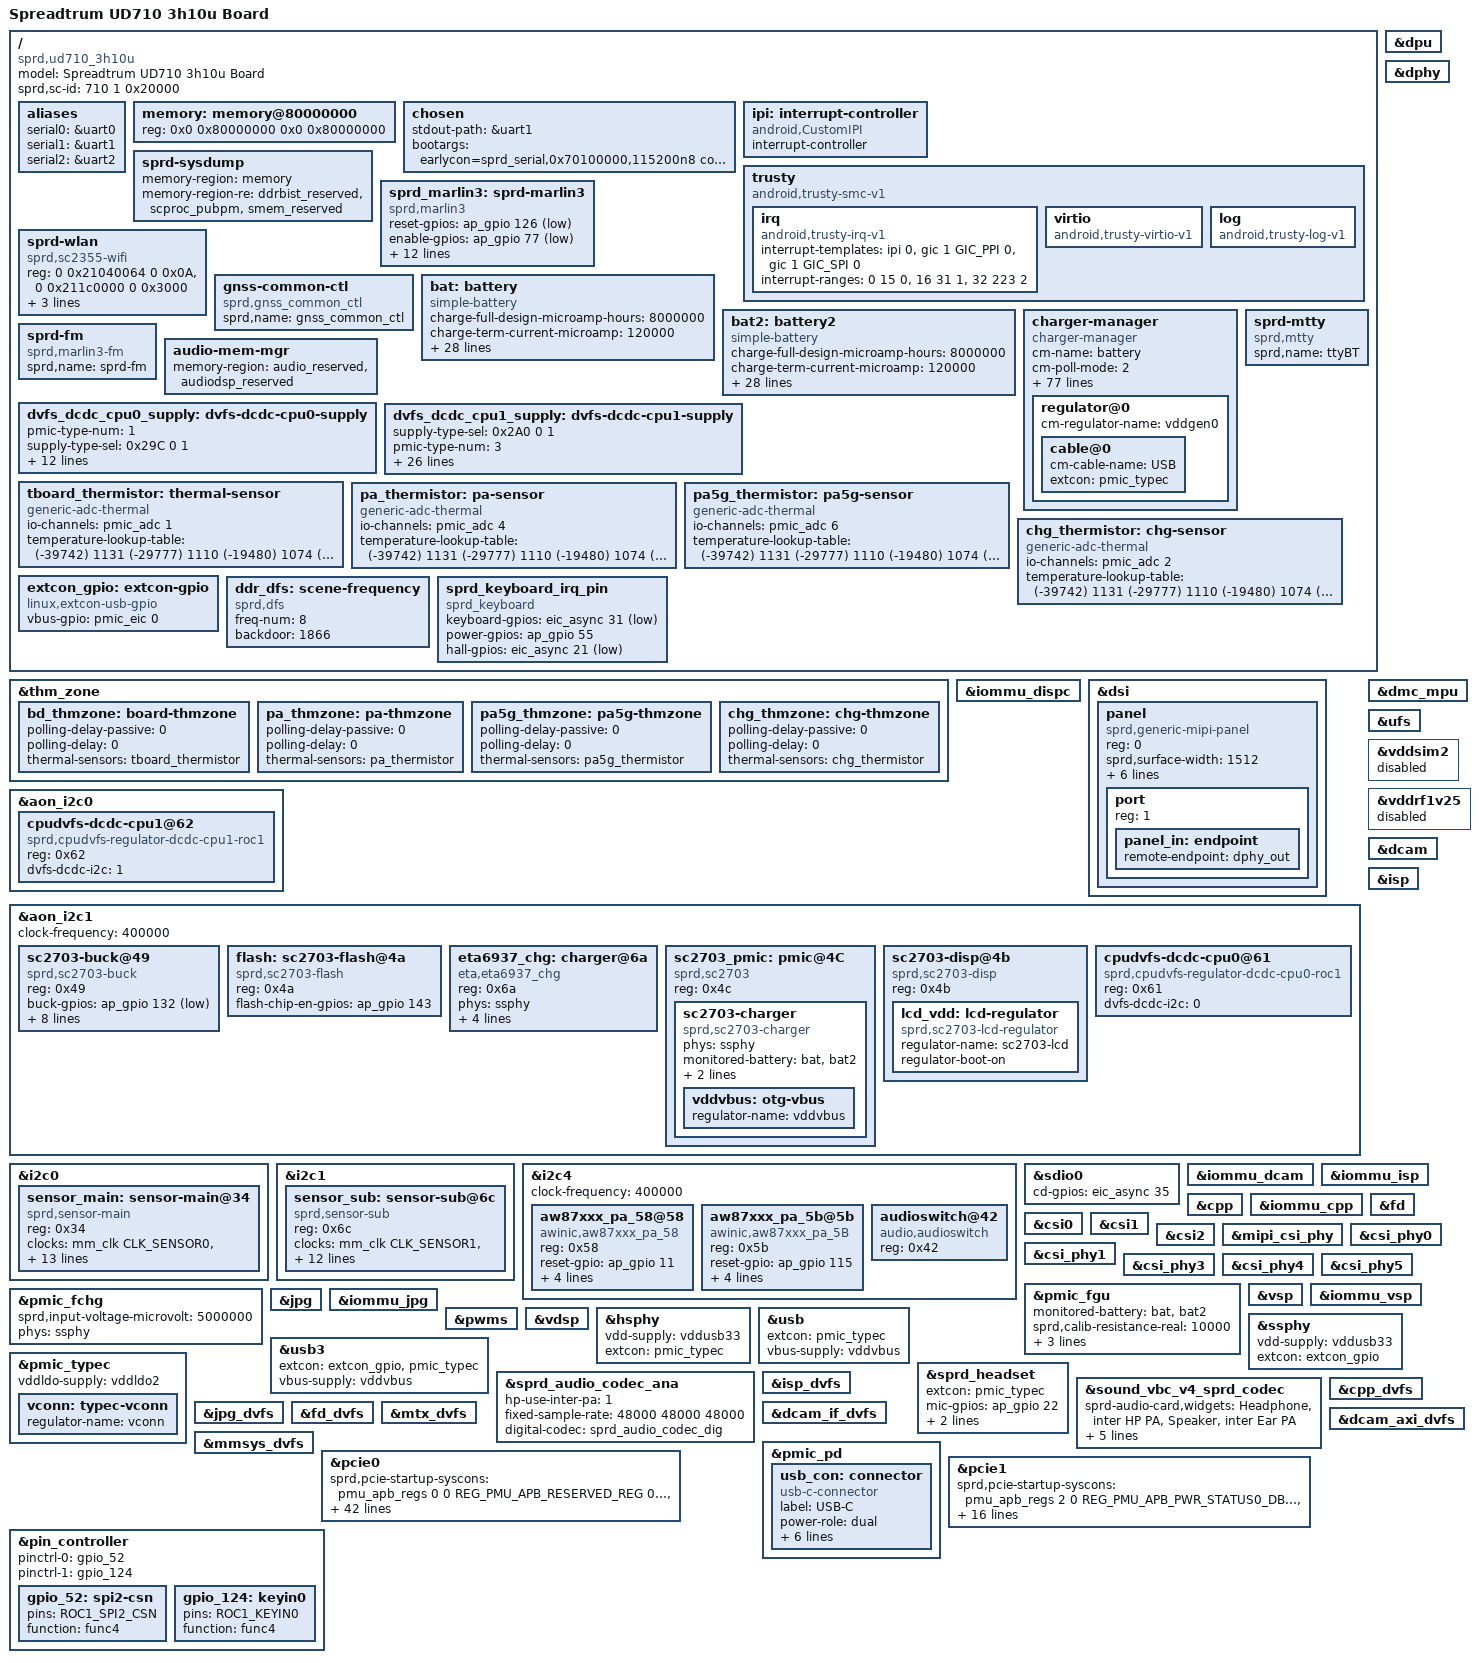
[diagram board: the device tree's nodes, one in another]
/*
 * Spreadtrum Roc1 board DTS file
 *
 * Copyright (C) 2018, Spreadtrum Communications Inc.
 *
 * This file is licensed under a dual GPLv2 or X11 license.
 */
/dts-v1/;

#include <dt-bindings/gpio/gpio.h>
#include <dt-bindings/usb/pd.h>

#include "ud710.dtsi"
#include "sc2730.dtsi"
#include "ud710-3h10u-mach.dtsi"
#include "ud710-2h10-modem.dtsi"
#include "sprd-sound-fe-be.dtsi"
#include "lcd/lcd_dummy_mipi.dtsi"

#include "lcd/lcd_rm69380_lattice_fpga_mipi.dtsi"

/ {
	model = "Spreadtrum UD710 3h10u Board";

	compatible = "sprd,ud710_3h10u", "sprd,ud710";

	sprd,sc-id = <710 1 0x20000>;

	aliases {
		serial0 = &uart0;
		serial1 = &uart1;
		serial2 = &uart2;
	};

	memory: memory@80000000 {
		device_type = "memory";
		reg = <0x0 0x80000000 0x0 0x80000000>;
	};

	chosen {
		stdout-path = &uart1;
		bootargs = "earlycon=sprd_serial,0x70100000,115200n8 console=ttyS1,115200n8 loop.max_part=7 loglevel=1 init=/init root=/dev/raw0 rw rootwait androidboot.hardware=ud710_3h10u androidboot.dtbo_idx=0 printk.devkmsg=on pcie_ports=compat";
	};

	ipi: interrupt-controller {
		compatible = "android,CustomIPI";
		#interrupt-cells = <1>;
		interrupt-controller;
	};

	trusty {
		compatible = "android,trusty-smc-v1";

		irq {
			compatible = "android,trusty-irq-v1";
			interrupt-templates = <&ipi 0>,
						<&gic 1 GIC_PPI 0>,
						<&gic 1 GIC_SPI 0>;
			interrupt-ranges = < 0  15 0>,
						<16  31 1>,
						<32 223 2>;
		};

		virtio {
			compatible = "android,trusty-virtio-v1";
		};

		log {
			compatible = "android,trusty-log-v1";
		};
	};

	sprd-sysdump {
		memory-region = <&memory>;
		memory-region-re = <&ddrbist_reserved>, <&scproc_pubpm>, <&smem_reserved>;
	};

	sprd_marlin3: sprd-marlin3 {
		compatible = "sprd,marlin3";
		reset-gpios = <&ap_gpio 126 GPIO_ACTIVE_LOW>;
		enable-gpios = <&ap_gpio 77 GPIO_ACTIVE_LOW>;
		m2-to-ap-irq-gpios = <&ap_gpio 96 GPIO_ACTIVE_LOW>;
		xtal-26m-clk-type = "TCXO";
		/* no need config dvdd12 because of share vddmem to DDR */
		avdd12-supply = <&vddgen1>;
		avdd33-supply = <&vddwifipa>;
		dcxo18-supply = <&vddldo0>;
		clock-names = "clk_32k","source","enable";
		clocks = <&aon_clk CLK_AON_AUX0>,
			 <&ext_32k>,
			 <&aonapb_gate CLK_AUX0_EB>;
		sprd,btwf-file-name = "/dev/block/by-name/wcnmodem";
		sprd,gnss-file-name = "/dev/block/by-name/gnssmodem";
		sprd,rc-ctrl = <&pcie0>;
	};

	sprd-wlan {
		compatible = "sprd,sc2355-wifi";
		reg = <0 0x21040064 0 0x0A>,
		      <0 0x211c0000 0 0x3000>;
		reg-names = "wifi_ipaqos",
			    "pam_wifi_reg_base_remap";
		syscons = <&ipa_ahb_regs
			   REG_IPA_AHB_IPA_EB
			   MASK_IPA_AHB_PAM_WIFI_EB>;
		syscon-names = "enable";
	};

	gnss-common-ctl {
		compatible = "sprd,gnss_common_ctl";
		sprd,name = "gnss_common_ctl";
	};

	bat: battery {
		compatible = "simple-battery";
		charge-full-design-microamp-hours = <8000000>;
		charge-term-current-microamp = <120000>;
		constant_charge_voltage_max_microvolt = <4400000>;
		factory-internal-resistance-micro-ohms = <80000>;
		voltage-min-design-microvolt = <3490000>;
		ocv-capacity-celsius = <20>;
		ocv-capacity-table-0 = <4334000 100>, <4272000 95>, <4218000 90>,
					<4160000 85>, <4109000 80>, <4068000 75>,
					<3999000 70>, <3964000 65>, <3923000 60>,
					<3876000 55>, <3847000 50>, <3824000 45>,
					<3803000 40>, <3787000 35>, <3773000 30>,
					<3757000 25>, <3742000 20>, <3720000 15>,
					<3689000 10>, <3675000 5>, <3400000 0>;
		voltage-temp-table = <1084000 800>, <975000 850>, <868000 900>,
				      <765000 950>, <668000 1000>, <580000 1050>,
				      <501000 1100>, <430000 1150>, <369000 1200>,
				      <315000 1250>, <270000 1300>, <231000 1350>,
				      <197000 1400>, <169000 1450>, <145000 1500>,
				      <125000 1550>, <108000 1600>, <93000 1650>;
		capacity-temp-table = <45 100>, <25 100>, <10 97>, <0 95>, <(-10) 82>, <(-20) 62>;
		resistance-temp-table = <45 100>, <25 100>, <10 483>, <0 680>, <(-10) 789>, <(-20) 816>;
		charge-sdp-current-microamp = <500000 500000>;
		charge-dcp-current-microamp = <2500000 3000000>;
		charge-cdp-current-microamp = <1500000 1500000>;
		charge-unknown-current-microamp = <2000000 2500000>;
		charge-fchg-current-microamp = <1650000 1000000>;
	};
	
	bat2: battery2 {
		compatible = "simple-battery";
		charge-full-design-microamp-hours = <8000000>;
		charge-term-current-microamp = <120000>;
		constant_charge_voltage_max_microvolt = <4400000>;
		factory-internal-resistance-micro-ohms = <80000>;
		voltage-min-design-microvolt = <3490000>;
		ocv-capacity-celsius = <20>;
		ocv-capacity-table-0 = <4326000 100>, <4262000 95>, <4209000 90>,
					<4150000 85>, <4100000 80>, <4050000 75>,
					<3999000 70>, <3964000 65>, <3918000 60>,
					<3872000 55>, <3838000 50>, <3817000 45>,
					<3798000 40>, <3782000 35>, <3769000 30>,
					<3756000 25>, <3737000 20>, <3715000 15>,
					<3683000 10>, <3672000 5>, <3400000 0>;
		voltage-temp-table = <1084000 800>, <975000 850>, <868000 900>,
				      <765000 950>, <668000 1000>, <580000 1050>,
				      <501000 1100>, <430000 1150>, <369000 1200>,
				      <315000 1250>, <270000 1300>, <231000 1350>,
				      <197000 1400>, <169000 1450>, <145000 1500>,
				      <125000 1550>, <108000 1600>, <93000 1650>;
		capacity-temp-table = <45 100>, <25 100>, <10 97>, <0 95>, <(-10) 82>, <(-20) 62>;
		resistance-temp-table = <45 100>, <25 100>, <10 483>, <0 680>, <(-10) 789>, <(-20) 816>;
		charge-sdp-current-microamp = <500000 500000>;
		charge-dcp-current-microamp = <2500000 3000000>;
		charge-cdp-current-microamp = <1500000 1500000>;
		charge-unknown-current-microamp = <2000000 2500000>;
		charge-fchg-current-microamp = <1650000 1000000>;
	};

	charger-manager {
		compatible = "charger-manager";
		cm-name = "battery";
		cm-poll-mode = <2>;
		cm-poll-interval = <15000>;
		cm-battery-stat = <2>;

		cm-fullbatt-vchkdrop-ms = <30000>;
		cm-fullbatt-vchkdrop-volt = <60000>;
		cm-fullbatt-voltage = <4320000 4320000>;
		cm-first-fullbatt-current = <150000>;
		cm-fullbatt-current = <200000>;
		cm-fullbatt-capacity = <100>;

		cm-num-chargers = <2>;
		cm-num-fast-chargers = <1>;
		cm-chargers = "sc2703_charger","eta6937_charger";
		cm-fast-chargers = "sc2730_fast_charger";
		cm-fuel-gauge = "sc27xx-fgu";

		/* in deci centigrade */
		cm-battery-cold = <200>;
		cm-battery-cold-in-minus;
		cm-battery-hot = <800>;
		cm-battery-temp-diff = <100>;

		/* Allow charging for 10hr */
		cm-charging-max = <36000000>;
		/* recovery charging after stop charging 3hr */
		cm-discharging-max = <10800000>;

		/* the interval to feed charger watchdog */
		cm-wdt-interval = <60>;

		/* drop voltage in microVolts to allow shutdown */
		cm-shutdown-voltage = <3400000>;

		/* when 99% of the time is exceeded, it will be forced to 100% */
		cm-tickle-time-out = <500>;

		/* how much time to allow capacity change */
		cm-one-cap-time = <30>;

		/* when the safe charging voltage is exceeded, stop charging */
		cm-charge-voltage-max = <6500000>;
		/* drop voltage in microVolts to restart charging */
		cm-charge-voltage-drop = <700000>;

		/* when the safe charging voltage is exceeded, stop charging */
		cm-fast-charge-voltage-max = <10500000>;
		/* drop voltage in microVolts to restart charging */
		cm-fast-charge-voltage-drop = <700000>;

		cm-double-ic-total-limit-current = <2000000>;
		cm-fchg-compensation-current = <3600000>;
        cm-dcp-jeita-temp-table = <1000 1030 0 4100000>, <1100 1130 1550000 4100000>,
            <1450 1420 2500000 4350000>, <1600 1570 1550000 4100000>;
        cm-dcp-jeita-temp-table-1 = <1000 1030 0 4100000>, <1100 1130 1550000 4100000>,
            <1450 1420 2500000 4350000>, <1600 1570 1550000 4100000>;
        cm-sdp-jeita-temp-table = <1000 1030 0 4100000>, <1100 1130 500000 4100000>,
            <1450 1420 500000 4350000>, <1600 1570 500000 4100000>;
        cm-sdp-jeita-temp-table-1 = <1000 1030 0 4100000>, <1100 1130 500000 4100000>,
            <1450 1420 500000 4350000>, <1600 1570 500000 4100000>;
        cm-cdp-jeita-temp-table = <1000 1030 0 4100000>, <1100 1130 700000 4100000>,
            <1450 1420 2000000 4350000>, <1600 1570 1550000 4100000>;
        cm-cdp-jeita-temp-table-1 = <1000 1030 0 4100000>, <1100 1130 700000 4100000>,
            <1450 1420 2000000 4350000>, <1600 1570 1550000 4100000>;
        cm-unknown-jeita-temp-table = <1000 1030 0 4100000>, <1100 1130 1550000 4100000>,
            <1450 1420 2000000 4350000>, <1600 1570 1550000 4100000>;
        cm-unknown-jeita-temp-table-1 = <1000 1030 0 4100000>, <1100 1130 1550000 4100000>,
            <1450 1420 2000000 4350000>, <1600 1570 1550000 4100000>;
        cm-fchg-jeita-temp-table = <1000 1030 0 4100000>, <1100 1130 1000000 4100000>,
            <1450 1420 1650000 4350000>, <1600 1570 1000000 4100000>;
        cm-fchg-jeita-temp-table-1 = <1000 1030 0 4100000>, <1100 1130 1000000 4100000>,
            <1450 1420 1650000 4350000>, <1600 1570 1000000 4100000>;


		monitored-battery = <&bat &bat2>;
		cm-capacity-track;

		regulator@0 {
			cm-regulator-name = "vddgen0";
			cable@0 {
				cm-cable-name = "USB";
				extcon = <&pmic_typec>;
			};
		};
	};

	sprd-mtty {
		compatible = "sprd,mtty";
		sprd,name = "ttyBT";
	};

	sprd-fm {
		compatible = "sprd,marlin3-fm";
		sprd,name = "sprd-fm";
	};

	audio-mem-mgr {
		memory-region = <&audio_reserved &audiodsp_reserved>;
	};

	dvfs_dcdc_cpu0_supply: dvfs-dcdc-cpu0-supply {
		pmic-type-num = <1>;
		supply-type-sel = <0x29C 0 1>;
		top-dvfs-i2c-state = <0x88 4 0xF>;
		voltage-grade-num = <7>;
		voltage-grade = <0 0x2D 0x260 0 0xFFFF>,	/* 0.75 */
				<1 0x32 0x260 16 0xFFFF>,	/* 0.80 */
				<2 0x37 0x264 0 0xFFFF>,	/* 0.85 */
				<3 0x3C 0x264 16 0xFFFF>,	/* 0.90 */
				<4 0x41 0x268 0 0xFFFF>,	/* 0.95 */
				<5 0x46 0x268 16 0xFFFF>,	/* 1.00 */
				<6 0x4B 0x26C 0 0xFFFF>;	/* 1.05 */
		tuning-latency-us = <200>;
		chnl-in-i2c = <1>;
		slew-rate = <20000>; /* 20000uV/us */
	};

	dvfs_dcdc_cpu1_supply: dvfs-dcdc-cpu1-supply {
		supply-type-sel = <0x2A0 0 1>;
		pmic-type-num = <3>;
		top-dvfs-i2c-state = <0x8C 4 0xF>;
		voltage-grade-num = <7>;
		voltage-grade = <0 0x4B 0x280 0 0xFFFF>,	/* 0.75 */
				<1 0x50 0x280 16 0xFFFF>,	/* 0.80 */
				<2 0x55 0x284 0 0xFFFF>,	/* 0.85 */
				<3 0x5A 0x284 16 0xFFFF>,	/* 0.90 */
				<4 0x5F 0x288 0 0xFFFF>,	/* 0.95 */
				<5 0x64 0x288 16 0xFFFF>,	/* 1.00 */
				<6 0x69 0x28c 0 0xFFFF>;	/* 1.05 */
		voltage-up-delay = <50 0x130 0 0xffff 0x1600>,
				<100 0x130 16 0xffff 0x1a00>,
				<150 0x134 0 0xffff 0x1f00>,
				<200 0x134 16 0xffff 0x2400>,
				<250 0x138 0 0xffff 0x2900>,
				<300 0x138 16 0xffff 0x2e00>,
				<350 0x13c 0 0xffff 0x3300>;
		voltage-down-delay = <50 0x140 0 0xffff 0x1600>,
				<100 0x140 16 0xffff 0x1a00>,
				<150 0x144 0 0xffff 0x1f00>,
				<200 0x144 16 0xffff 0x2400>,
				<250 0x148 0 0xffff 0x2900>,
				<300 0x148 16 0xffff 0x2e00>,
				<350 0x14c 0 0xffff 0x3300>;
		tuning-latency-us = <200>;
		chnl-in-i2c = <1>;
		slew-rate = <10000>; /* 10000uV/us */
	};

	tboard_thermistor:thermal-sensor {
		compatible = "generic-adc-thermal";
		#thermal-sensor-cells = <0>;
		io-channels = <&pmic_adc 1>;
		io-channel-names = "sensor-channel";
		temperature-lookup-table = <	(-39742) 1131
						(-29777) 1110
						(-19480) 1074
						(-4679) 983
						10110 838
						24805 654
						44922 413
						54903 316
						64895 238
						74884 178
						84883 133
						94883 100
						104880 75
						114889 57
						124872 43 >;
	};

	pa_thermistor:pa-sensor {
		compatible = "generic-adc-thermal";
		#thermal-sensor-cells = <0>;
		io-channels = <&pmic_adc 4>;
		io-channel-names = "sensor-channel";
		temperature-lookup-table = <	(-39742) 1131
			(-29777) 1110
			(-19480) 1074
			(-4679) 983
			10110 838
			24805 654
			44922 413
			54903 316
			64895 238
			74884 178
			84883 133
			94883 100
			104880 75
			114889 57
			124872 43 >;
	};

	pa5g_thermistor:pa5g-sensor {
		compatible = "generic-adc-thermal";
		#thermal-sensor-cells = <0>;
		io-channels = <&pmic_adc 6>;
		io-channel-names = "sensor-channel";
		temperature-lookup-table = <	(-39742) 1131
			(-29777) 1110
			(-19480) 1074
			(-4679) 983
			10110 838
			24805 654
			44922 413
			54903 316
			64895 238
			74884 178
			84883 133
			94883 100
			104880 75
			114889 57
			124872 43 >;
	};

	chg_thermistor:chg-sensor {
		compatible = "generic-adc-thermal";
		#thermal-sensor-cells = <0>;
		io-channels = <&pmic_adc 2>;
		io-channel-names = "sensor-channel";
		temperature-lookup-table = <	(-39742) 1131
			(-29777) 1110
			(-19480) 1074
			(-4679) 983
			10110 838
			24805 654
			44922 413
			54903 316
			64895 238
			74884 178
			84883 133
			94883 100
			104880 75
			114889 57
			124872 43 >;
	};
	extcon_gpio: extcon-gpio {
		compatible = "linux,extcon-usb-gpio";
		vbus-gpio = <&pmic_eic 0 GPIO_ACTIVE_HIGH>;
	};

	ddr_dfs: scene-frequency {
		compatible = "sprd,dfs";
		freq-num = <8>;
		backdoor = <1866>;
	};
    sprd_keyboard_irq_pin {
        compatible = "sprd_keyboard";
        keyboard-gpios = <&eic_async 31 GPIO_ACTIVE_LOW>;
        power-gpios = <&ap_gpio 55 0>;
        hall-gpios = <&eic_async 21 GPIO_ACTIVE_LOW>;
    };
};

&dpu {
	status = "okay";
};

&thm_zone {
	bd_thmzone: board-thmzone {
		polling-delay-passive = <0>;
		polling-delay = <0>;
		thermal-sensors = <&tboard_thermistor>;
	};
	pa_thmzone: pa-thmzone {
		polling-delay-passive = <0>;
		polling-delay = <0>;
		thermal-sensors = <&pa_thermistor>;
	};

	pa5g_thmzone: pa5g-thmzone {
		polling-delay-passive = <0>;
		polling-delay = <0>;
		thermal-sensors = <&pa5g_thermistor>;
	};

	chg_thmzone: chg-thmzone {
		polling-delay-passive = <0>;
		polling-delay = <0>;
		thermal-sensors = <&chg_thermistor>;
	};
};

&iommu_dispc {
	status = "okay";
};

&dsi {
	status = "okay";
	#address-cells = <1>;
	#size-cells = <0>;

	panel: panel {
		compatible = "sprd,generic-mipi-panel";
		#address-cells = <1>;
		#size-cells = <0>;
		reg = <0>;
		sprd,surface-width = <1512>;
		sprd,surface-height = <2072>;
		reset-gpio = <&ap_gpio 50 GPIO_ACTIVE_HIGH>;
		lcd1v8-gpio = <&ap_gpio 60 GPIO_ACTIVE_HIGH>;
		fpga1v8-gpio = <&ap_gpio 72 GPIO_ACTIVE_HIGH>;
		fpga1v2-gpio = <&ap_gpio 73 GPIO_ACTIVE_HIGH>;
		//fpgarst-gpio = <&ap_gpio 137 GPIO_ACTIVE_HIGH>;
		power-supply = <&lcd_vdd>;
		port {
			reg = <1>;
			panel_in: endpoint {
				remote-endpoint = <&dphy_out>;
			};
		};
	};
};

//&vddldo2 {
//	regulator-always-on;
//	status = "okay";
//};
//
//&vddldo1 {
//	regulator-always-on;
//	status = "okay";
//};

&dphy {
	status = "okay";
};

&aon_i2c0 {
	status = "okay";

	/* A virtual i2c device */
	cpudvfs-dcdc-cpu1@62{
		compatible = "sprd,cpudvfs-regulator-dcdc-cpu1-roc1";
		reg = <0x62>;
		dvfs-dcdc-i2c = <1>;
	};
};

&aon_i2c1 {
	status = "okay";
	clock-frequency = <400000>;

	sc2703-buck@49 {
		compatible = "sprd,sc2703-buck";
		reg = <0x49>;
		buck-gpios = <&ap_gpio 132 GPIO_ACTIVE_LOW>;

		sprd,buck-ch1-b-out = <1000000>;

		regulator-name = "sc2703-buck";
		regulator-min-microvolt = < 300000>;
		regulator-max-microvolt = <1570000>;
		regulator-min-microamp = <5600000>;
		regulator-max-microamp = <10800000>;
		regulator-boot-on;
		regulator-always-on;
	};

	flash: sc2703-flash@4a {
		compatible = "sprd,sc2703-flash";
		reg = <0x4a>;
		flash-chip-en-gpios = <&ap_gpio 143 0>;
	};

	eta6937_chg: charger@6a {
		compatible = "eta,eta6937_chg";
		reg = <0x6a>;
		phys = <&ssphy>;
		monitored-battery = <&bat &bat2>;
		chg-enable-gpios = <&ap_gpio 83 GPIO_ACTIVE_HIGH>;
		extcon = <&pmic_typec>;
		status="okay";
		role-slave;
	};

	sc2703_pmic: pmic@4C {
		compatible = "sprd,sc2703";
		reg = <0x4c>;
		sc2703-charger {
			compatible = "sprd,sc2703-charger";
			phys = <&ssphy>;
			monitored-battery = <&bat &bat2>;
			extcon = <&pmic_typec>, <&pmic_pd>;
			sprd,long-key-detection;
			vddvbus:otg-vbus {
				regulator-name = "vddvbus";
			};
		};
	};
	sc2703-disp@4b {
		compatible = "sprd,sc2703-disp";
		reg = <0x4b>;

		lcd_vdd: lcd-regulator {
			compatible = "sprd,sc2703-lcd-regulator";
			regulator-name = "sc2703-lcd";
			regulator-boot-on;
		};
	};

	/* A virtual i2c device */
	cpudvfs-dcdc-cpu0@61{
		compatible = "sprd,cpudvfs-regulator-dcdc-cpu0-roc1";
		reg = <0x61>;
		dvfs-dcdc-i2c = <0>;
	};
};

&i2c0 {
	status = "okay";

	sensor_main: sensor-main@34 {
		compatible = "sprd,sensor-main";
		reg = <0x34>;

		clock-names = "clk_src","sensor_eb",
			"clk_96m","clk_76m8",
			"clk_48m","clk_26m";
		clocks = <&mm_clk CLK_SENSOR0>,<&mm_gate CLK_MM_SENSOR0_EB>,
			<&g12_pll CLK_TWPLL_96M>,<&g12_pll CLK_TWPLL_76M8>,
			<&g12_pll CLK_TWPLL_48M>,<&ext_26m>;
		vddio-supply = <&vddcamio>;
		vddcama-supply = <&vddcama0>;
		vddcamd-supply = <&vddcamd0>;
		vddcammot-supply = <&vddcammot>;
		sprd,phyid = <0>;
		csi = <&csi0>;
		reset-gpios = <&ap_gpio 44 0>;
		power-down-gpios = <&ap_gpio 46 0>;
		avdd-gpios = <&ap_gpio 162 0>;

		status = "okay";
	};
};

&i2c1 {
	status = "okay";

	sensor_sub: sensor-sub@6c {
		compatible = "sprd,sensor-sub";
		reg = <0x6c>;

		clock-names = "clk_src","sensor_eb",
			"clk_96m","clk_76m8",
			"clk_48m","clk_26m";
		clocks = <&mm_clk CLK_SENSOR1>,<&mm_gate CLK_MM_SENSOR1_EB>,
			<&g12_pll CLK_TWPLL_96M>,<&g12_pll CLK_TWPLL_76M8>,
			<&g12_pll CLK_TWPLL_48M>,<&ext_26m>;
		vddio-supply = <&vddcamio>;
		vddcama-supply = <&vddcama1>;
		vddcamd-supply = <&vddcamd1>;
		vddcammot-supply = <&vddcammot>;
		sprd,phyid = <5>;
		csi = <&csi1>;
		reset-gpios = <&ap_gpio 45 0>;
		power-down-gpios = <&ap_gpio 47 0>;
		/*avdd-gpios = <&ap_gpio 140 0>;*/

		status = "okay";
	};
/*
	sensor_main2: sensor-main2@20 {
		compatible = "sprd,sensor-main2";
		reg = <0x20>;

		clock-names = "clk_src","sensor_eb",
			"clk_96m","clk_76m8",
			"clk_48m","clk_26m";
		clocks = <&mm_clk CLK_SENSOR0>,<&mm_gate CLK_MM_SENSOR0_EB>,
			<&g12_pll CLK_TWPLL_96M>,<&g12_pll CLK_TWPLL_76M8>,
			<&g12_pll CLK_TWPLL_48M>,<&ext_26m>;
		vddio-supply = <&vddcamio>;
		vddcama-supply = <&vddcama1>;
		vddcamd-supply = <&vddcamd1>;
		vddcammot-supply = <&vddcammot>;
		sprd,phyid = <4>;
		csi = <&csi1>;
		reset-gpios = <&ap_gpio 138 0>;
		power-down-gpios = <&ap_gpio 137 0>;

		status = "okay";
	};
*/
};

&i2c4 {
	status = "okay";
	clock-frequency = <400000>;

    aw87xxx_pa_58@58 {
        compatible = "awinic,aw87xxx_pa_58";
        reg = <0x58>;
        reset-gpio = <&ap_gpio 11 0>;
        monitor-flag = <1>;
        driver-num = < 0 >;
        monitor-timer-val = <3000>;
        monitor-timer-count-max = <5>;
        status = "okay";
    };

    aw87xxx_pa_5b@5b {
        compatible = "awinic,aw87xxx_pa_5B";
        reg = <0x5b>;
        reset-gpio = <&ap_gpio 115 0>;
        monitor-flag = <1>;
        driver-num = < 1 >;
        monitor-timer-val = <3000>;
        monitor-timer-count-max = <5>;
        status = "okay";
    };
    audioswitch@42 {
	status = "okay";
	compatible = "audio,audioswitch";
	reg = <0x42>;
    };
};

&dmc_mpu {
	status = "okay";
};

&sdio0 {
	cd-gpios = <&eic_async 35 GPIO_ACTIVE_HIGH>;
};

&ufs {
	status = "okay";
};


&vddsim2 {
	status = "disabled";
};

&vddrf1v25 {
	status = "disabled";
};

&dcam {
	status = "okay";
};

&iommu_dcam {
	status = "okay";
};

&isp {
	status = "okay";
};

&iommu_isp {
	status = "okay";
};

&cpp {
	status = "okay";
};

&iommu_cpp {
	status = "okay";
};

&fd{
	status = "okay";
};

&csi0{
	status = "okay";
};

&csi1{
	status = "okay";
};

&csi2{
	status = "okay";
};

&mipi_csi_phy {
	status = "okay";
};

&csi_phy0{
	status = "okay";
};

&csi_phy1{
	status = "okay";
};

&csi_phy3{
	status = "okay";
};

&csi_phy4{
	status = "okay";
};

&csi_phy5{
	status = "okay";
};

&pmic_fgu {
	monitored-battery = <&bat &bat2>;
	sprd,calib-resistance-real = <10000>;
	sprd,calib-resistance-spec = <20000>;
	first-calib-voltage = <3630000>;
	first-calib-capacity = <50>;
};

&pmic_fchg {
	sprd,input-voltage-microvolt = <5000000>;
	phys = <&ssphy>;
};

&vsp {
	status = "okay";
};

&iommu_vsp {
	status = "okay";
};

&jpg {
	status = "okay";
};

&iommu_jpg {
	status = "okay";
};

&pwms {
	status = "okay";
};

&vdsp {
	status = "okay";
};

&hsphy {
	vdd-supply = <&vddusb33>;
	extcon = <&pmic_typec>;
	status = "okay";
};

&usb {
	extcon = <&pmic_typec>;
	vbus-supply = <&vddvbus>;
	status = "okay";
};

&ssphy {
	vdd-supply = <&vddusb33>;
	extcon = <&extcon_gpio>;
	status = "okay";
};

&usb3 {
	extcon = <&extcon_gpio>, <&pmic_typec>;
	vbus-supply = <&vddvbus>;
	status = "okay";
};

&pmic_typec {
	vddldo-supply = <&vddldo2>;
	status = "okay";
	vconn: typec-vconn {
		regulator-name = "vconn";
	};
};

&sprd_headset {
	status = "okay";
	extcon = <&pmic_typec>;
	mic-gpios = <&ap_gpio 22 GPIO_ACTIVE_HIGH>;
	lr-gpios = <&ap_gpio 23 GPIO_ACTIVE_HIGH>;
	sprd,3pole-adc-threshold = <112>;
};

&sprd_audio_codec_ana {
	status = "okay";
	hp-use-inter-pa = <1>;
	fixed-sample-rate = <48000 48000 48000>;
	digital-codec = <&sprd_audio_codec_dig>;
};

&sound_vbc_v4_sprd_codec {

    status = "okay";
    sprd-audio-card,widgets =
        "Headphone", "inter HP PA",
        "Speaker", "inter Ear PA";
    sprd-audio-card,routing =
        "HPMIC Pin", "HP Mic Jack",
        "MIC Pin", "Mic Jack",
        "MIC2 Pin", "Aux Mic Jack",
        "inter HP PA", "HP Pin",
        "Ext Spk", "HP Pin",
        "DMIC Pin", "DMic Jack",
        "DMIC1 Pin", "DMic1 Jack",
        "inter Ear PA", "EAR Pin";
};

&isp_dvfs {
	status = "okay";
};

&cpp_dvfs {
	status = "okay";
};

&jpg_dvfs {
	status = "okay";
};

&fd_dvfs {
	status = "okay";
};

&mtx_dvfs {
	status = "okay";
};

&dcam_if_dvfs {
	status = "okay";
};

&dcam_axi_dvfs {
	status = "okay";
};

&mmsys_dvfs {
	status = "okay";
};

&pmic_pd {
	status = "okay";
	usb_con: connector {
		compatible = "usb-c-connector";
		label = "USB-C";
		power-role = "dual";
		try-power-role = "sink";
		source-pdos = <PDO_FIXED(5000, 400, PDO_FIXED_USB_COMM)>;
		sink-pdos = <PDO_FIXED(5000, 2000, PDO_FIXED_USB_COMM)>;
		op-sink-microwatt = <10000000>;
	};
};

&pcie0 {
	sprd,pcie-startup-syscons =
		<&pmu_apb_regs 0 0
			REG_PMU_APB_RESERVED_REG
			0x10000
			0>,
		<&anlg_phy_g13_regs 0 0
			REG_ANLG_PHY_G13_ANALOG_PCIEPLL_H_PCIEPLL_H_CTRL0
			MASK_ANLG_PHY_G6_ANALOG_PCIEPLL_V_DIFF_OR_SING_SEL
			0>,
		<&anlg_phy_g13_regs 1 0
			REG_ANLG_PHY_G13_ANALOG_PCIEPLL_H_PCIEPLL_H_CTRL0
			MASK_ANLG_PHY_G13_ANALOG_PCIEPLL_H_RG_PCIEPLLH_DIVN
			(0x1f << 9)>,
		<&pmu_apb_regs 0 0
			REG_PMU_APB_PCIEPLL_H_REL_CFG
			MASK_PMU_APB_PCIEPLL_H_FRC_ON
			(0x1 << 8)>,
		<&pmu_apb_regs 0 0
			REG_PMU_APB_ANALOG_PHY_PWRON_CFG
			MASK_PMU_APB_PCIE2_PWRON_REG
			(0x1 << 2)>,
		<&pmu_apb_regs 2 0
			REG_PMU_APB_SLEEP_STATUS
			MASK_PMU_APB_IPA_SLP_STATUS
			(0x6 << 24)>,
		<&pmu_apb_regs 2 0
			REG_PMU_APB_PWR_STATUS0_DBG
			MASK_PMU_APB_PD_IPA_SYS_STATE
			0x0>,
		<&ipa_ahb_regs 0 0
			REG_IPA_AHB_IPA_EB
			MASK_IPA_AHB_PCIE2_EB
			(0x1 << 8)>,
		/*
		 * Remain 100M reference clock to active at least 150us to make
		 * sure that it's stable before pulling high perst#.
		 */
		<&anlg_phy_g13_regs 0 150
			REG_ANLG_PHY_G13_ANALOG_PCIEPLL_H_PCIEPLL_H_CTRL0
			MASK_ANLG_PHY_G6_ANALOG_PCIEPLL_V_DIFF_OR_SING_SEL
			1>,
		<&pmu_apb_regs 0 2000
			REG_PMU_APB_PCIE_PERST_CTRL_CFG
			MASK_PMU_APB_REG_PCIE2_PERST_N_ASSERT
			0>;

	sprd,pcie-shutdown-syscons =
		<&pmu_apb_regs 0 0
			REG_PMU_APB_PCIE_PERST_CTRL_CFG
			MASK_PMU_APB_REG_PCIE2_PERST_N_ASSERT
			(0x1 << 1)>,
		<&anlg_phy_g13_regs 0 0
			REG_ANLG_PHY_G13_ANALOG_PCIEPLL_H_PCIEPLL_H_CTRL0
			MASK_ANLG_PHY_G6_ANALOG_PCIEPLL_V_DIFF_OR_SING_SEL
			0>,
		<&ipa_ahb_regs 0 0
			REG_IPA_AHB_IPA_EB
			MASK_IPA_AHB_PCIE2_EB
			0>,
		<&pmu_apb_regs 0 0
			REG_PMU_APB_ANALOG_PHY_PWRON_CFG
			MASK_PMU_APB_PCIE2_PWRON_REG
			0>,
		<&pmu_apb_regs 0 0
			REG_PMU_APB_ANALOG_PHY_PD_CFG
			MASK_PMU_APB_PCIE2_PD_REG
			(0x1 << 2)>,
		/* IPA_SYS power up without waiting for PCIEPLL_H (pcie gen2) */
		<&pmu_apb_regs 0 0
			REG_PMU_APB_PCIEPLL_H_REL_CFG
			MASK_PMU_APB_PCIEPLL_H_IPA_SEL
			0>,
		<&pmu_apb_regs 0 0
			REG_PMU_APB_PCIEPLL_H_REL_CFG
			MASK_PMU_APB_PCIEPLL_H_FRC_ON
			0>;

	sprd,pcie-resume-syscons =
		<&pmu_apb_regs 0 200
			REG_PMU_APB_PCIEPLL_H_REL_CFG
			MASK_PMU_APB_PCIEPLL_H_FRC_ON
			(0x1 << 8)>,
		<&pmu_apb_regs 0 0
			REG_PMU_APB_ANALOG_PHY_PWRON_CFG
			MASK_PMU_APB_PCIE2_PWRON_REG
			(0x1 << 2)>,
		<&pmu_apb_regs 2 0
			REG_PMU_APB_SLEEP_STATUS
			MASK_PMU_APB_IPA_SLP_STATUS
			(0x6 << 24)>,
		<&pmu_apb_regs 2 0
			REG_PMU_APB_PWR_STATUS0_DBG
			MASK_PMU_APB_PD_IPA_SYS_STATE
			0x0>,
		<&ipa_ahb_regs 0 200
			REG_IPA_AHB_IPA_EB
			MASK_IPA_AHB_PCIE2_EB
			(0x1 << 8)>,
		<&anlg_phy_g13_regs 1 0
			REG_ANLG_PHY_G13_ANALOG_PCIEPLL_H_PCIEPLL_H_CTRL0
			MASK_ANLG_PHY_G13_ANALOG_PCIEPLL_H_RG_PCIEPLLH_DIVN
			(0x1f << 9)>,
		<&anlg_phy_g13_regs 0 150
			REG_ANLG_PHY_G13_ANALOG_PCIEPLL_H_PCIEPLL_H_CTRL0
			MASK_ANLG_PHY_G6_ANALOG_PCIEPLL_V_DIFF_OR_SING_SEL
			1>,
		<&pmu_apb_regs 0 2000
			REG_PMU_APB_PCIE_PERST_CTRL_CFG
			MASK_PMU_APB_REG_PCIE2_PERST_N_ASSERT
			0>;

	sprd,pcie-suspend-syscons =
		<&pmu_apb_regs 0 0
			REG_PMU_APB_PCIE_PERST_CTRL_CFG
			MASK_PMU_APB_REG_PCIE2_PERST_N_ASSERT
			(0x1 << 1)>,
		<&anlg_phy_g13_regs 0 0
			REG_ANLG_PHY_G13_ANALOG_PCIEPLL_H_PCIEPLL_H_CTRL0
			MASK_ANLG_PHY_G6_ANALOG_PCIEPLL_V_DIFF_OR_SING_SEL
			0>,
		<&ipa_ahb_regs 0 0
			REG_IPA_AHB_IPA_EB
			MASK_IPA_AHB_PCIE2_EB
			0>,
		<&pmu_apb_regs 0 0
			REG_PMU_APB_ANALOG_PHY_PWRON_CFG
			MASK_PMU_APB_PCIE2_PWRON_REG
			0>,
		<&pmu_apb_regs 0 0
			REG_PMU_APB_ANALOG_PHY_PD_CFG
			MASK_PMU_APB_PCIE2_PD_REG
			(0x1 << 2)>,
		<&pmu_apb_regs 0 0
			REG_PMU_APB_PCIEPLL_H_REL_CFG
			MASK_PMU_APB_PCIEPLL_H_IPA_SEL
			0>,
		<&pmu_apb_regs 0 0
			REG_PMU_APB_PCIEPLL_H_REL_CFG
			MASK_PMU_APB_PCIEPLL_H_FRC_ON
			0>;

	sprd,pcie-aspml1p2-syscons =
		<&anlg_pcie20_phy_regs 1 0
			REG_PIPE_CFGA_ANA_CFG13
			MASK_PIPE_CFGA_ANA_CFG13_CFG_FORCE_REFCLK_EN
			(0x1 << 23)>,
		/* enter gen1 low power mode */
		<&anlg_pcie20_phy_regs 1 0
			REG_PIPE_CFGA_ANA_CFG13
			MASK_PIPE_CFGA_ANA_CFG13_CFG_G1_ONLY
			(0x1 << 28)>,
		/*
		 * delay time between PCIEPLL_H_PD deassert and
		 * PCIEPLL_H_RST deassert
		 */
		<&pmu_apb_regs 1 0
			REG_PMU_APB_PCIEPLL_H_RST_CTRL_CFG
			MASK_PMU_APB_PCIEPLL_H_DELAY_PWR_ON
			(0x4e << 16)>,
		/*
		 * delay time between PCIEPLL_H_RST assert and
		 * PCIEPLL_H_PD assert
		 */
		<&pmu_apb_regs 1 0
			REG_PMU_APB_PCIEPLL_H_RST_CTRL_CFG
			MASK_PMU_APB_PCIEPLL_H_DELAY_RST_ASSERT
			0x4e>,
		/*
		 * wait for 145us after CLKREQ# pulled low to make sure 100M
		 * reference is stable
		 */
		<&pmu_apb_regs 1 0
			REG_PMU_APB_PLL_WAIT_CNT3
			MASK_PMU_APB_PCIEPLL_H_WAIT_CNT
			0x5>,
		/* auto gate 100M reference clock of pcie gen2 phy */
		<&pmu_apb_regs 1 0
			REG_PMU_APB_RESERVED_REG
			(0x1 << 16)     /* no corresponding macro */
			0>,
		/* auto gate 100M reference pll of pcie gen2 phy */
		<&pmu_apb_regs 1 0
			REG_PMU_APB_RESERVED_REG
			0x1     /* no corresponding macro */
			0x1>;
};

&pcie1 {
	sprd,pcie-startup-syscons =
		<&pmu_apb_regs 2 0
			 REG_PMU_APB_PWR_STATUS0_DBG
			 MASK_PMU_APB_PD_IPA_SYS_STATE
			 0x0>,
		<&anlg_phy_g6_regs 1 0
			 REG_ANLG_PHY_G6_ANALOG_PCIEPLL_V_PCIEPLL_V_CTRL6
			 0x3000
			 0x1000>,
		<&anlg_phy_g6_regs 1 0
			 REG_ANLG_PHY_G6_ANALOG_PCIEPLL_V_PCIEPLL_V_CTRL0
			 MASK_ANLG_PHY_G6_ANALOG_PCIEPLL_V_RG_PCIEPLLV_DIVN
			 0x3e00>,
		<&anlg_phy_g6_regs 0 0
			 REG_ANLG_PHY_G6_ANALOG_PCIEPLL_V_PCIEPLL_V_CTRL0
			 MASK_ANLG_PHY_G6_ANALOG_PCIEPLL_V_DIFF_OR_SING_SEL
			 0x1>,
		<&pmu_apb_regs 0 150
			 REG_PMU_APB_PCIEPLL_V_REL_CFG
			 MASK_PMU_APB_PCIEPLL_V_FRC_ON
			 0x100>,
		<&ipa_ahb_regs 0 150
			 REG_IPA_AHB_IPA_EB
			 MASK_IPA_AHB_PCIE3_EB
			 0x80>,
		<&pmu_apb_regs 0 2000
			 REG_PMU_APB_PCIE_PERST_CTRL_CFG
			 MASK_PMU_APB_REG_PCIE3_PERST_N_ASSERT
			 0x0>;
	sprd,pcie-resume-syscons =
		<&pmu_apb_regs 2 0
			 REG_PMU_APB_PWR_STATUS0_DBG
			 MASK_PMU_APB_PD_IPA_SYS_STATE
			 0x0>,
		<&pmu_apb_regs 0 150
			 REG_PMU_APB_PCIEPLL_V_REL_CFG
			 MASK_PMU_APB_PCIEPLL_V_FRC_ON
			 0x100>,
		<&ipa_ahb_regs 0 150
			 REG_IPA_AHB_IPA_EB
			 MASK_IPA_AHB_PCIE3_EB
			 0x80>,
		<&pmu_apb_regs 0 2000
			 REG_PMU_APB_PCIE_PERST_CTRL_CFG
			 MASK_PMU_APB_REG_PCIE3_PERST_N_ASSERT
			 0x0>;
	sprd,pcie-suspend-syscons =
		<&pmu_apb_regs 0 0
			 REG_PMU_APB_PCIE_PERST_CTRL_CFG
			 MASK_PMU_APB_REG_PCIE3_PERST_N_ASSERT
			 0x8>,
		<&ipa_ahb_regs 0 0
			 REG_IPA_AHB_IPA_EB
			 MASK_IPA_AHB_PCIE3_EB
			 0x0>,
		/* IPA_SYS power up without waiting for PCIEPLL_V (pcie gen3) */
		<&pmu_apb_regs 0 0
			REG_PMU_APB_PCIEPLL_V_REL_CFG
			MASK_PMU_APB_PCIEPLL_V_IPA_SEL
			0>,
		<&pmu_apb_regs 0 0
			 REG_PMU_APB_PCIEPLL_V_REL_CFG
			 MASK_PMU_APB_PCIEPLL_V_FRC_ON
			 0x0>;
};

&pin_controller {
	pinctrl-names =
	/* spi2-csn, keyin0 */
	"gpio_52", "gpio_124";

	pinctrl-0 = <&gpio_52>;
	pinctrl-1 = <&gpio_124>;

	gpio_52: spi2-csn {
		pins = "ROC1_SPI2_CSN";
		function = "func4";
	};

	gpio_124: keyin0 {
		pins = "ROC1_KEYIN0";
		function = "func4";
	};
};

